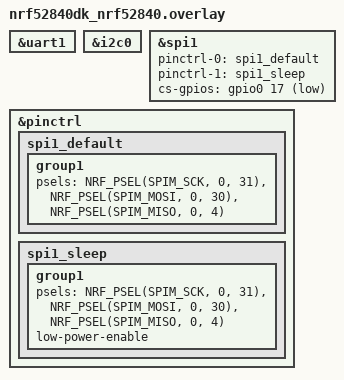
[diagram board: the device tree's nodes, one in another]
dev_a: &uart1 {
	status = "okay";
};

dev_b: &i2c0 {
	status = "okay";
};

dev_c: &spi1 {
	status = "okay";
	pinctrl-0 = <&spi1_default>;
	pinctrl-1 = <&spi1_sleep>;
	pinctrl-names = "default", "sleep";
	cs-gpios = <&gpio0 17 GPIO_ACTIVE_LOW>;
};

&pinctrl {
	spi1_default: spi1_default {
		group1 {
			psels = <NRF_PSEL(SPIM_SCK, 0, 31)>,
				<NRF_PSEL(SPIM_MOSI, 0, 30)>,
				<NRF_PSEL(SPIM_MISO, 0, 4)>;
		};
	};
	spi1_sleep: spi1_sleep {
		group1 {
			psels = <NRF_PSEL(SPIM_SCK, 0, 31)>,
				<NRF_PSEL(SPIM_MOSI, 0, 30)>,
				<NRF_PSEL(SPIM_MISO, 0, 4)>;
			low-power-enable;
		};
	};
};
